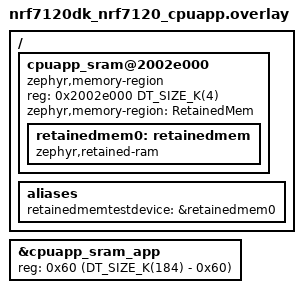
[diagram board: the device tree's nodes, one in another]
/*
 * Copyright (c) 2026 Nordic Semiconductor ASA
 *
 * SPDX-License-Identifier: Apache-2.0
 */

/ {
	cpuapp_sram@2002e000 {
		compatible = "zephyr,memory-region", "mmio-sram";
		reg = <0x2002e000 DT_SIZE_K(4)>;
		zephyr,memory-region = "RetainedMem";
		status = "okay";

		retainedmem0: retainedmem {
			compatible = "zephyr,retained-ram";
			status = "okay";
		};
	};

	aliases {
		retainedmemtestdevice = &retainedmem0;
	};
};

&cpuapp_sram_app {
	reg = <0x60 (DT_SIZE_K(184) - 0x60)>;
};
